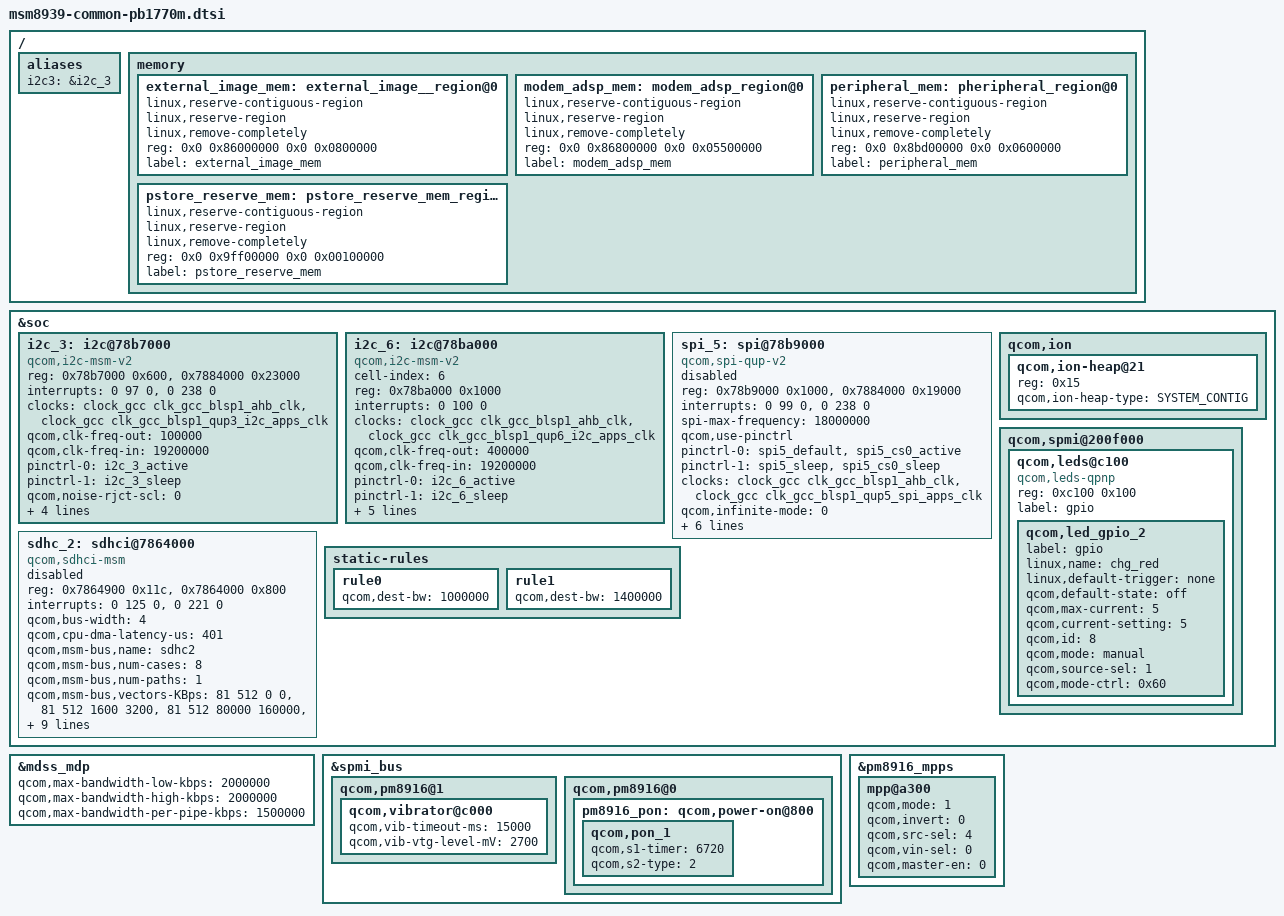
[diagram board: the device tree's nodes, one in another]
/* Copyright (c) 2020, The Linux Foundation. All rights reserved.
*  Copyright (c) 2015, Lenovo.
*  Copyright (c) 2020, the_shahnawaz_sheikh (sheikhshahnawaz41299).
*
* This program is free software; you can redistribute it and/or modify
* it under the terms of the GNU General Public License version 2 and
* only version 2 as published by the Free Software Foundation.
*
* This program is distributed in the hope that it will be useful,
* but WITHOUT ANY WARRANTY; without even the implied warranty of
* MERCHANTABILITY or FITNESS FOR A PARTICULAR PURPOSE.  See the
* GNU General Public License for more details.
*/

/ {
	aliases {
		i2c3 = &i2c_3;
		/delete-property/ spi0;
	};
	
	memory {
		#address-cells = <2>;
		#size-cells = <2>;

		external_image_mem: external_image__region@0 {
			linux,reserve-contiguous-region;
			linux,reserve-region;
			linux,remove-completely;
			reg = <0x0 0x86000000 0x0 0x0800000>;
			label = "external_image_mem";
		};

		modem_adsp_mem: modem_adsp_region@0 {
			linux,reserve-contiguous-region;
			linux,reserve-region;
			linux,remove-completely;
			reg = <0x0 0x86800000 0x0 0x05500000>;
			label = "modem_adsp_mem";
		};

		peripheral_mem: pheripheral_region@0 {
			linux,reserve-contiguous-region;
			linux,reserve-region;
			linux,remove-completely;
			reg = <0x0 0x8bd00000 0x0 0x0600000>;
			label = "peripheral_mem";
		};

		pstore_reserve_mem: pstore_reserve_mem_region@0 {
			linux,reserve-contiguous-region;
			linux,reserve-region;
			linux,remove-completely;
			reg = <0x0 0x9ff00000 0x0 0x00100000>;
			label = "pstore_reserve_mem";
		};
	};
};

&soc {
		
		/delete-node/ spi@78b7000;
		
		
   i2c_3: i2c@78b7000 { /* BLSP1 QUP2 */
		compatible = "qcom,i2c-msm-v2";
		#address-cells = <1>;
		#size-cells = <0>;
		reg-names = "qup_phys_addr", "bam_phys_addr";
		reg = <0x78b7000 0x600>,
		      <0x7884000 0x23000>;
		interrupt-names = "qup_irq", "bam_irq";
		interrupts = <0 97 0>, <0 238 0>;
		clocks = <&clock_gcc clk_gcc_blsp1_ahb_clk>,
			 <&clock_gcc clk_gcc_blsp1_qup3_i2c_apps_clk>;
		clock-names = "iface_clk", "core_clk";
		qcom,clk-freq-out = <100000>;
		qcom,clk-freq-in  = <19200000>;
		pinctrl-names = "i2c_active", "i2c_sleep";
		pinctrl-0 = <&i2c_3_active>;
		pinctrl-1 = <&i2c_3_sleep>;
		qcom,noise-rjct-scl = <0>;
		qcom,noise-rjct-sda = <0>;
		qcom,bam-pipe-idx-cons = <8>;
		qcom,bam-pipe-idx-prod = <9>;
		qcom,master-id = <86>;
	};
	
	i2c_6: i2c@78ba000 { /* BLSP1 QUP6 */
		compatible = "qcom,i2c-msm-v2";
		#address-cells=<1>;
		#size-cells=<0>;
		cell-index = <6>;
		reg-names = "qup_phys_addr";
		reg = <0x78ba000 0x1000>;
		interrupt-names = "qup_irq";
		interrupts = <0 100 0>;
		clocks = <&clock_gcc clk_gcc_blsp1_ahb_clk>,
			 <&clock_gcc clk_gcc_blsp1_qup6_i2c_apps_clk>;
		clock-names = "iface_clk", "core_clk";
		qcom,clk-freq-out = <400000>;
		qcom,clk-freq-in  = <19200000>;
		pinctrl-names = "i2c_active", "i2c_sleep";
		pinctrl-0 = <&i2c_6_active>;
		pinctrl-1 = <&i2c_6_sleep>;
		qcom,noise-rjct-scl = <0>;
		qcom,noise-rjct-sda = <0>;
		dmas = <&dma_blsp1 14 64 0x20000020 0x20>,
			<&dma_blsp1 15 32 0x20000020 0x20>;
		dma-names = "tx", "rx";
		qcom,master-id = <86>;
	};
	
	spi_5: spi@78b9000 {  /* BLSP1 QUP5 */
		compatible = "qcom,spi-qup-v2";
		#address-cells = <1>;
		#size-cells = <0>;
		reg-names = "spi_physical", "spi_bam_physical";
		reg = <0x78b9000 0x1000>,
			<0x7884000 0x19000>;
		interrupt-names = "spi_irq", "spi_bam_irq";
		interrupts = <0 99 0>, <0 238 0>;
		spi-max-frequency = <18000000>;
		qcom,use-pinctrl;
		pinctrl-names = "spi_default", "spi_sleep";
		pinctrl-0 = <&spi5_default &spi5_cs0_active>;
		pinctrl-1 = <&spi5_sleep &spi5_cs0_sleep>;
		clocks = <&clock_gcc clk_gcc_blsp1_ahb_clk>,
			<&clock_gcc clk_gcc_blsp1_qup5_spi_apps_clk>;
		clock-names = "iface_clk", "core_clk";
		qcom,infinite-mode = <0>;
		qcom,use-bam;
		qcom,ver-reg-exists;
		qcom,bam-consumer-pipe-index = <12>;
		qcom,bam-producer-pipe-index = <13>;
		qcom,master-id = <86>;
		qcom,rt-priority;
		status = "disabled";
	};
	
	sdhc_2: sdhci@7864000 {
		compatible = "qcom,sdhci-msm";
		reg = <0x7864900 0x11c>, <0x7864000 0x800>;
		reg-names = "hc_mem", "core_mem";

		interrupts = <0 125 0>, <0 221 0>;
		interrupt-names = "hc_irq", "pwr_irq";
		
		status = "ok";

		qcom,bus-width = <4>;
		qcom,cpu-dma-latency-us = <401>;
		qcom,msm-bus,name = "sdhc2";
		qcom,msm-bus,num-cases = <8>;
		qcom,msm-bus,num-paths = <1>;
		qcom,msm-bus,vectors-KBps = <81 512 0 0>, /* No vote */
				<81 512 1600 3200>,    /* 400 KB/s*/
				<81 512 80000 160000>, /* 20 MB/s */
				<81 512 100000 200000>, /* 25 MB/s */
				<81 512 200000 400000>, /* 50 MB/s */
				<81 512 400000 800000>, /* 100 MB/s */
				<81 512 400000 800000>, /* 200 MB/s */
				<81 512 2048000 4096000>; /* Max. bandwidth */
		qcom,bus-bw-vectors-bps = <0 400000 20000000 25000000 50000000
						100000000 200000000 4294967295>;

		clocks = <&clock_gcc clk_gcc_sdcc2_ahb_clk>,
			 <&clock_gcc clk_gcc_sdcc2_apps_clk>;
		clock-names = "iface_clk", "core_clk";

		qcom,clk-rates = <400000 25000000 50000000 100000000 177770000>;

		status = "disabled";
	};
	
	qcom,ion {
	     
		 qcom,ion-heap@21 {
				reg = <0x15>;
				qcom,ion-heap-type = "SYSTEM_CONTIG";
			};
	};
	
	static-rules {
	    
		 rule0 {
		      qcom,dest-bw = <1000000>;
		};
		
		rule1 {
		      qcom,dest-bw = <1400000>;
		};
	};
		 
};

&mdss_mdp {
    qcom,max-bandwidth-low-kbps = <2000000>;
	qcom,max-bandwidth-high-kbps = <2000000>;
	qcom,max-bandwidth-per-pipe-kbps = <1500000>;
	/delete-property/ qcom,max-bw-settings;
};

&spmi_bus {

     qcom,pm8916@1 {
		qcom,vibrator@c000 {
			status = "okay";
			qcom,vib-timeout-ms = <15000>;
			qcom,vib-vtg-level-mV = <2700>;
		};
	};
  
     qcom,pm8916@0 {
     
	    pm8916_pon: qcom,power-on@800 {
	             qcom,pon_1 {
		                qcom,s1-timer = <6720>;
			            qcom,s2-type = <2>;
	             };
        };
     };
};	 

&soc {
   
   qcom,spmi@200f000 {
	 qcom,leds@c100 {
			compatible = "qcom,leds-qpnp";
			reg = <0xc100 0x100>;
			label = "gpio";
			status = "okay";
			qcom,led_gpio_2 {
				label = "gpio";
				linux,name = "chg_red";
				linux,default-trigger = "none";
				qcom,default-state = "off";
				qcom,max-current = <5>;
				qcom,current-setting = <5>;
				qcom,id = <8>;
				qcom,mode = "manual";
				qcom,source-sel = <1>;
				qcom,mode-ctrl = <0x60>;
			};
		};
	};
};

&pm8916_mpps {
	mpp@a300 { /* MPP 4 */
		/* Backlight PWM */
		qcom,mode = <1>;		/* Digital output */
		qcom,invert = <0>;		/* Disable invert */
		qcom,src-sel = <4>;		/* DTEST1 */
		qcom,vin-sel = <0>;		/* VPH_PWR */
		qcom,master-en = <0>;		/* Enable MPP */
	};
};
		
